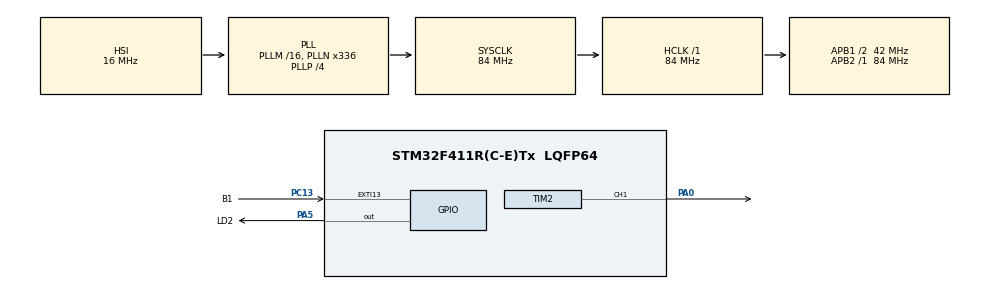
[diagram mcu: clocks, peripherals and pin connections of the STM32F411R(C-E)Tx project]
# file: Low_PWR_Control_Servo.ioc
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Mcu.Family=STM32F4
PC15-OSC32_OUT.Mode=LSE-External-Oscillator
RCC.CortexFreq_Value=84000000
PC13-ANTI_TAMP.GPIO_Label=B1
PA14.GPIO_Label=TCK
PH1\ -\ OSC_OUT.Mode=HSE-External-Clock-Source
RCC.APB1CLKDivider=RCC_HCLK_DIV2
PC14-OSC32_IN.Signal=RCC_OSC32_IN
RCC.SYSCLKSource=RCC_SYSCLKSOURCE_PLLCLK
ProjectManager.StackSize=0x400
PA0-WKUP.Signal=S_TIM2_CH1_ETR
TIM2.Pulse-PWM\ Generation1\ CH1=1000
PA13.Signal=SYS_JTMS-SWDIO
PH0\ -\ OSC_IN.Mode=HSE-External-Clock-Source
PH0\ -\ OSC_IN.Signal=RCC_OSC_IN
ProjectManager.TargetToolchain=STM32CubeIDE
RCC.HCLKFreq_Value=84000000
RCC.APB2TimFreq_Value=84000000
PC15-OSC32_OUT.Signal=RCC_OSC32_OUT
RCC.AHBFreq_Value=84000000
NVIC.EXTI15_10_IRQn=true\:0\:0\:false\:false\:true\:true\:true
PA5.Signal=GPIO_Output
RCC.HSE_VALUE=8000000
PH1\ -\ OSC_OUT.Signal=RCC_OSC_OUT
board=NUCLEO-F411RE
PC13-ANTI_TAMP.Signal=GPXTI13
RCC.VCOOutputFreq_Value=336000000
RCC.APB2Freq_Value=84000000
PC14-OSC32_IN.Mode=LSE-External-Oscillator
VP_TIM2_VS_ClockSourceINT.Mode=Internal
PA14.Mode=Serial_Wire
TIM2.Channel-PWM\ Generation1\ CH1=TIM_CHANNEL_1
TIM2.Period=20000
PA13.Mode=Serial_Wire
Mcu.Name=STM32F411R(C-E)Tx
PA13.GPIO_Label=TMS
RCC.FLatency-AdvancedSettings=FLASH_LATENCY_2
RCC.48MHZClocksFreq_Value=84000000
PB3.Signal=SYS_JTDO-SWO
RCC.SYSCLKFreq_VALUE=84000000
Mcu.Package=LQFP64
TIM2.Prescaler=31
PA5.GPIO_Label=LD2
SH.S_TIM2_CH1_ETR.0=TIM2_CH1,PWM Generation1 CH1
PA14.Signal=SYS_JTCK-SWCLK
ProjectManager.HeapSize=0x200
RCC.HSI_VALUE=16000000
RCC.PLLP=RCC_PLLP_DIV4
NVIC.PriorityGroup=NVIC_PRIORITYGROUP_0
RCC.PLLN=336
RCC.APB1TimFreq_Value=84000000
RCC.APB1Freq_Value=42000000
PB3.GPIO_Label=SWO

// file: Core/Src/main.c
/* USER CODE BEGIN Header */
/**
  ******************************************************************************
  * @file           : main.c
  * @brief          : Main program body
  ******************************************************************************
  * @attention
  *
  * <h2><center>&copy; Copyright (c) 2021 STMicroelectronics.
  * All rights reserved.</center></h2>
  *
  * This software component is licensed by ST under BSD 3-Clause license,
  * the "License"; You may not use this file except in compliance with the
  * License. You may obtain a copy of the License at:
  *                        opensource.org/licenses/BSD-3-Clause
  *
  ******************************************************************************
  */
/* USER CODE END Header */
#include "main.h"
#include "tim.h"
#include "gpio.h"

/* USER CODE BEGIN Includes */
#include "servo.h"
/* USER CODE END Includes */

/* USER CODE BEGIN PV */
uint16_t angle;
servo_t servo;
volatile uint8_t StopModeFlag = 0; //volatile for interrupt
/* USER CODE END PV */

void SystemClock_Config(void);

int main(void)
{

  /* MCU Configuration--------------------------------------------------------*/

  /* Reset of all peripherals, Initializes the Flash interface and the Systick. */
  HAL_Init();

  /* Configure the system clock */
  SystemClock_Config();

  /* Initialize all configured peripherals */
  MX_GPIO_Init();
  MX_TIM2_Init();
  /* USER CODE BEGIN 2 */
  Servo_Init(&servo, &htim2, TIM_CHANNEL_1);
  /* USER CODE END 2 */

  /* Infinite loop */
  while (1)
  {

    /* USER CODE BEGIN 3 */
	  Servo_SetAngle(&servo, 0);
	  HAL_Delay(1000);

	  Servo_SetAngle(&servo, 90);
	  HAL_Delay(1000);

	  Servo_SetAngleFine(&servo, 160.16);
	  HAL_Delay(1000);

	  HAL_GPIO_TogglePin(LD2_GPIO_Port, LD2_Pin);
	  HAL_Delay(1000);

	  HAL_SuspendTick(); // Halt SysTick to prevent Wakeup

	  if(StopModeFlag == 0)
	  {
		  StopModeFlag = 1;
	 	  HAL_PWR_EnterSTOPMode(PWR_LOWPOWERREGULATOR_ON, PWR_SLEEPENTRY_WFI);
	  }

	  if(StopModeFlag == 1)
	  {
		  SystemClock_Config(); //Reconfigure the clocks
		  StopModeFlag = 0;
	  }

	 HAL_ResumeTick(); // Resume SysTick to work further
  }
  /* USER CODE END 3 */
}

void SystemClock_Config(void)
{
  RCC_OscInitTypeDef RCC_OscInitStruct = {0};
  RCC_ClkInitTypeDef RCC_ClkInitStruct = {0};

  /** Configure the main internal regulator output voltage
  */
  __HAL_RCC_PWR_CLK_ENABLE();
  __HAL_PWR_VOLTAGESCALING_CONFIG(PWR_REGULATOR_VOLTAGE_SCALE1);
  /** Initializes the RCC Oscillators according to the specified parameters
  * in the RCC_OscInitTypeDef structure.
  */
  RCC_OscInitStruct.OscillatorType = RCC_OSCILLATORTYPE_HSI;
  RCC_OscInitStruct.HSIState = RCC_HSI_ON;
  RCC_OscInitStruct.HSICalibrationValue = RCC_HSICALIBRATION_DEFAULT;
  RCC_OscInitStruct.PLL.PLLState = RCC_PLL_ON;
  RCC_OscInitStruct.PLL.PLLSource = RCC_PLLSOURCE_HSI;
  RCC_OscInitStruct.PLL.PLLM = 16;
  RCC_OscInitStruct.PLL.PLLN = 336;
  RCC_OscInitStruct.PLL.PLLP = RCC_PLLP_DIV4;
  RCC_OscInitStruct.PLL.PLLQ = 4;
  if (HAL_RCC_OscConfig(&RCC_OscInitStruct) != HAL_OK)
  {
    Error_Handler();
  }
  /** Initializes the CPU, AHB and APB buses clocks
  */
  RCC_ClkInitStruct.ClockType = RCC_CLOCKTYPE_HCLK|RCC_CLOCKTYPE_SYSCLK
                              |RCC_CLOCKTYPE_PCLK1|RCC_CLOCKTYPE_PCLK2;
  RCC_ClkInitStruct.SYSCLKSource = RCC_SYSCLKSOURCE_PLLCLK;
  RCC_ClkInitStruct.AHBCLKDivider = RCC_SYSCLK_DIV1;
  RCC_ClkInitStruct.APB1CLKDivider = RCC_HCLK_DIV2;
  RCC_ClkInitStruct.APB2CLKDivider = RCC_HCLK_DIV1;

  if (HAL_RCC_ClockConfig(&RCC_ClkInitStruct, FLASH_LATENCY_2) != HAL_OK)
  {
    Error_Handler();
  }
}

/* USER CODE BEGIN 4 */
//Interrupt handling
void HAL_GPIO_EXTI_Callback(uint16_t GPIO_Pin)
{
	  if(StopModeFlag == 1)
	  {
		  SystemClock_Config(); //Reconfigure the clocks
		  StopModeFlag = 0;
	  }
	//Display of the response confirmation on the terminal
	//HAL_UART_Transmit(&huart2, "Press button", sizeof("Press button"), 1000);
}
/* USER CODE END 4 */

void Error_Handler(void)
{
  __disable_irq();
  while (1)
  {
  }
}

/************************ (C) COPYRIGHT STMicroelectronics *****END OF FILE****/
